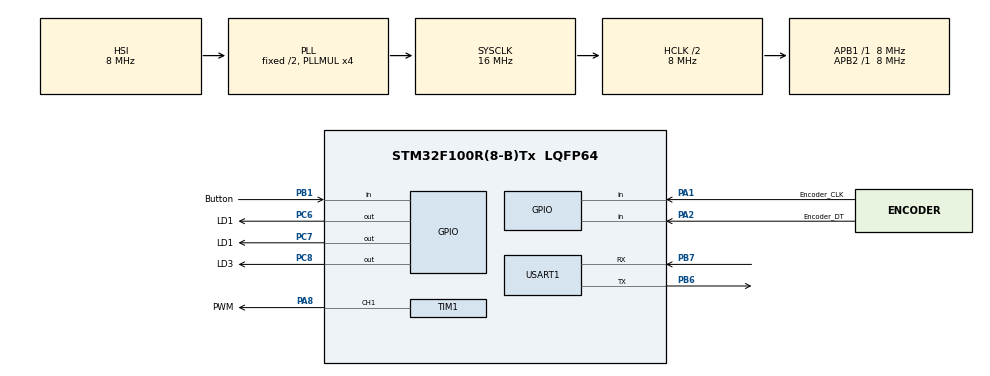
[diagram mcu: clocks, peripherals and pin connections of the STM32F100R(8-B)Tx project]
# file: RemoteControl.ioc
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Mcu.Family=STM32F1
Mcu.Name=STM32F100R(8-B)Tx
Mcu.Package=LQFP64
NVIC.PriorityGroup=NVIC_PRIORITYGROUP_4
NVIC.TIM1_UP_TIM16_IRQn=true\:0\:0\:false\:true\:true\:1\:true
NVIC.TIM6_DAC_IRQn=true\:0\:0\:false\:true\:true\:3\:true
NVIC.USART1_IRQn=true\:0\:0\:false\:true\:true\:2\:true
PA0-WKUP.Signal=SYS_WKUP
PA1.GPIO_Label=Encoder_CLK
PA1.GPIO_PuPd=GPIO_PULLDOWN
PA1.Signal=GPIO_Input
PA13.GPIO_Label=TMS_SWDIO
PA13.Mode=Trace_Asynchronous_SW
PA13.Signal=SYS_JTMS-SWDIO
PA14.GPIO_Label=TCK_SWCLK
PA14.Mode=Trace_Asynchronous_SW
PA14.Signal=SYS_JTCK-SWCLK
PA2.GPIO_Label=Encoder_DT
PA2.GPIO_PuPd=GPIO_PULLDOWN
PA2.Signal=GPIO_Input
PA8.GPIO_Label=PWM
PA8.GPIO_Speed=GPIO_SPEED_FREQ_HIGH
PA8.Signal=S_TIM1_CH1
PB1.GPIO_Label=Button
PB1.GPIO_PuPd=GPIO_PULLDOWN
PB1.Signal=GPIO_Input
PB3.Mode=Trace_Asynchronous_SW
PB3.Signal=SYS_JTDO-TRACESWO
PB6.Mode=Asynchronous
PB6.Signal=USART1_TX
PB7.Mode=Asynchronous
PB7.Signal=USART1_RX
PC14-OSC32_IN.Signal=RCC_OSC32_IN
PC15-OSC32_OUT.Signal=RCC_OSC32_OUT
PC6.GPIO_Label=LD1
PC6.GPIO_Speed=GPIO_SPEED_FREQ_HIGH
PC6.PinState=GPIO_PIN_SET
PC6.Signal=GPIO_Output
PC7.GPIO_Label=LD1
PC7.GPIO_Speed=GPIO_SPEED_FREQ_HIGH
PC7.PinState=GPIO_PIN_SET
PC7.Signal=GPIO_Output
PC8.GPIO_Label=LD3
PC8.GPIO_Speed=GPIO_SPEED_FREQ_HIGH
PC8.PinState=GPIO_PIN_SET
PC8.Signal=GPIO_Output
ProjectManager.HeapSize=0x200
ProjectManager.StackSize=0x400
ProjectManager.TargetToolchain=MDK-ARM V4
RCC.AHBCLKDivider=RCC_SYSCLK_DIV2
RCC.AHBFreq_Value=8000000
RCC.APB1Freq_Value=8000000
RCC.APB1TimFreq_Value=8000000
RCC.APB2Freq_Value=8000000
RCC.APB2TimFreq_Value=8000000
RCC.HCLKFreq_Value=8000000
RCC.PLLMUL=RCC_PLL_MUL4
RCC.SYSCLKFreq_VALUE=16000000
RCC.SYSCLKSource=RCC_SYSCLKSOURCE_PLLCLK
SH.S_TIM1_CH1.0=TIM1_CH1,PWM Generation1 CH1
TIM1.Channel-PWM\ Generation1\ CH1=TIM_CHANNEL_1
TIM1.Period=50000
TIM1.Prescaler=11
USART1.VirtualMode=VM_ASYNC
VP_TIM6_VS_ClockSourceINT.Mode=Enable_Timer
board=STM32VLDISCOVERY

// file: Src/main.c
/**
  ******************************************************************************
  * File Name          : main.c
  * Description        : Main program body
  ******************************************************************************
  ** This notice applies to any and all portions of this file
  * that are not between comment pairs USER CODE BEGIN and
  * USER CODE END. Other portions of this file, whether
  * inserted by the user or by software development tools
  * are owned by their respective copyright owners.
  *
  * COPYRIGHT(c) 2018 STMicroelectronics
  *
  * Redistribution and use in source and binary forms, with or without modification,
  * are permitted provided that the following conditions are met:
  *   1. Redistributions of source code must retain the above copyright notice,
  *      this list of conditions and the following disclaimer.
  *   2. Redistributions in binary form must reproduce the above copyright notice,
  *      this list of conditions and the following disclaimer in the documentation
  *      and/or other materials provided with the distribution.
  *   3. Neither the name of STMicroelectronics nor the names of its contributors
  *      may be used to endorse or promote products derived from this software
  *      without specific prior written permission.
  *
  * THIS SOFTWARE IS PROVIDED BY THE COPYRIGHT HOLDERS AND CONTRIBUTORS "AS IS"
  * AND ANY EXPRESS OR IMPLIED WARRANTIES, INCLUDING, BUT NOT LIMITED TO, THE
  * IMPLIED WARRANTIES OF MERCHANTABILITY AND FITNESS FOR A PARTICULAR PURPOSE ARE
  * DISCLAIMED. IN NO EVENT SHALL THE COPYRIGHT HOLDER OR CONTRIBUTORS BE LIABLE
  * FOR ANY DIRECT, INDIRECT, INCIDENTAL, SPECIAL, EXEMPLARY, OR CONSEQUENTIAL
  * DAMAGES (INCLUDING, BUT NOT LIMITED TO, PROCUREMENT OF SUBSTITUTE GOODS OR
  * SERVICES; LOSS OF USE, DATA, OR PROFITS; OR BUSINESS INTERRUPTION) HOWEVER
  * CAUSED AND ON ANY THEORY OF LIABILITY, WHETHER IN CONTRACT, STRICT LIABILITY,
  * OR TORT (INCLUDING NEGLIGENCE OR OTHERWISE) ARISING IN ANY WAY OUT OF THE USE
  * OF THIS SOFTWARE, EVEN IF ADVISED OF THE POSSIBILITY OF SUCH DAMAGE.
  *
  ******************************************************************************
  */

#include "main.h"
#include "stm32f1xx_hal.h"

/* USER CODE BEGIN Includes */

/* Modbus RTU */
#include "mb.h"
#include "mbport.h"
#include "registers.h"

/* USER CODE END Includes */

TIM_HandleTypeDef htim1;
TIM_HandleTypeDef htim6;

UART_HandleTypeDef huart1;

/* USER CODE BEGIN PV */
/* Private variables ---------------------------------------------------------*/

/* USER CODE END PV */

void SystemClock_Config(void);
static void MX_GPIO_Init(void);
static void MX_TIM1_Init(void);
static void MX_TIM6_Init(void);
static void MX_USART1_UART_Init(void);
static void MX_NVIC_Init(void);
void HAL_TIM_MspPostInit(TIM_HandleTypeDef *htim);

/* USER CODE BEGIN PFP */
/* Private function prototypes -----------------------------------------------*/

/* USER CODE END PFP */

int main(void)
{

  /* MCU Configuration----------------------------------------------------------*/

  /* Reset of all peripherals, Initializes the Flash interface and the Systick. */
  HAL_Init();

  /* Configure the system clock */
  SystemClock_Config();

  /* Initialize all configured peripherals */
  MX_GPIO_Init();
  MX_TIM1_Init();
  MX_TIM6_Init();
  MX_USART1_UART_Init();

  /* Initialize interrupts */
  MX_NVIC_Init();

  /* USER CODE BEGIN 2 */
  HAL_TIM_PWM_Start(&htim1, TIM_CHANNEL_1);
  eMBInit(MB_RTU, SLAVE_ADDRESS, USB, BAUDRATE, MB_PAR_NONE);
  eMBEnable();
  /* USER CODE END 2 */

  /* Infinite loop */
  /* USER CODE BEGIN WHILE */
  while (1)
  {
    static float PWM_duty = 0, TIM_period = 0, PWM_value = 0, analog_value = 0;
    static char button, led1, led2, led3, led_flag, prev_pos, counter_DT, counter_clk;
    static int  counter = 0;
    button = HAL_GPIO_ReadPin(GPIOB, GPIO_PIN_1);
    counter_DT = HAL_GPIO_ReadPin(GPIOA, GPIO_PIN_2);
    counter_clk = HAL_GPIO_ReadPin(GPIOA, GPIO_PIN_1);

    /* HC-SR04 value (echo) to % */
    /*
    if ((counter_echo_flag == ON) && (echo_pulse == ON))
      counter_echo++;
    else if ((counter_echo_flag == ON) && (echo_pulse == OFF))
      counter_echo_flag = OFF;
    if ((button_stm32 == ON) || (trigger_flag == OFF))
    {
        counter_echo_flag == ON;
        trigger_flag = ON;
    }
    if (trigger_flag == ON)
		{
      for (int i = 0; i < 50; i++)
				HAL_GPIO_WritePin(GPIOC, GPIO_PIN_6, GPIO_PIN_SET);
			HAL_GPIO_WritePin(GPIOC, GPIO_PIN_6, GPIO_PIN_RESET);
		}
    */

    /* Encoder code */
    if (counter_DT != prev_pos)
        {
            if (counter_DT != counter_clk)
              analog_value = analog_value + 1;
            else
              analog_value = analog_value - 1;;
            if (analog_value >= 100)
              analog_value = 100;
            if (analog_value <= 0)
              analog_value = 0;
        }

    /* Main logic */
    if (button == OFF)
    {
      if (analog_value < 20)
      {
        led1 = ON;
        led2 = ON;
        led3 = ON;
        PWM_value = 0;
      }
      if ((analog_value >= 20) && (analog_value < 60))
      {
        counter++;
        if (led_flag == OFF)
        {
          if (counter < LED_BLINK)
          {
            led1 = OFF;
            led_flag = OFF;
          }
          else if (counter > LED_BLINK)
          {
            led_flag = ON;
            counter = 0;
          }
        }
        if (led_flag == ON)
        {
          if (counter < LED_BLINK)
          {
            led1 = ON;
            led_flag = ON;
          }
          else if (counter > LED_BLINK)
          {
            led_flag = OFF;
            counter = 0;
          }
        }
        PWM_value = analog_value;
      }
      if ((analog_value >= 60) && (analog_value < 90))
      {
        led1 = ON;
        led3 = ON;
        counter++;
        if (led_flag == OFF)
        {
          if (counter < LED_BLINK)
          {
            led2 = OFF;
            led_flag = OFF;
          }
          else if (counter > LED_BLINK)
          {
            led_flag = ON;
            counter = 0;
          }
        }
        if (led_flag == ON)
        {
          if (counter < LED_BLINK)
          {
            led2 = ON;
            led_flag = ON;
          }
          else if (counter > LED_BLINK)
          {
            led_flag = OFF;
            counter = 0;
          }
        }

        PWM_value = 60;
      }
      if (analog_value >= 90)
      {
        led1 = ON;
        led2 = ON;
        counter++;
        if (led_flag == OFF)
        {
          if (counter < LED_BLINK)
          {
            led3 = OFF;
            led_flag = OFF;
          }
          else if (counter > LED_BLINK)
          {
            led_flag = ON;
            counter = 0;
          }
        }
        if (led_flag == ON)
        {
          if (counter < LED_BLINK)
          {
            led3 = ON;
            led_flag = ON;
          }
          else if (counter > LED_BLINK)
          {
            led_flag = OFF;
            counter = 0;
          }
        }
        PWM_value = 0;
      }
    }
    else if (button == ON)
    {
      led1 = OFF;
      led2 = OFF;
      counter++;
      if (led_flag == OFF)
      {
          if (counter < LED_BLINK)
          {
            led3 = OFF;
            led_flag = OFF;
          }
          else if (counter > LED_BLINK)
          {
            led_flag = ON;
            counter = 0;
          }
      }
      if (led_flag == ON)
      {
        if (counter < LED_BLINK)
        {
          led3 = ON;
          led_flag = ON;
        }
        else if (counter > LED_BLINK)
        {
          led_flag = OFF;
          counter = 0;
        }
      }
    PWM_value = (0.3333 * (analog_value));
		}

    if (led3 == ON)
      HAL_GPIO_WritePin(GPIOC, GPIO_PIN_9, GPIO_PIN_SET);
    else
      HAL_GPIO_WritePin(GPIOC, GPIO_PIN_9, GPIO_PIN_RESET);
    if (led1 == ON)
      HAL_GPIO_WritePin(GPIOC, GPIO_PIN_7, GPIO_PIN_SET);
    else
      HAL_GPIO_WritePin(GPIOC, GPIO_PIN_7, GPIO_PIN_RESET);
    if (led2 == ON)
      HAL_GPIO_WritePin(GPIOC, GPIO_PIN_8, GPIO_PIN_SET);
    else
      HAL_GPIO_WritePin(GPIOC, GPIO_PIN_8, GPIO_PIN_RESET);

    /* PWM duty by PWM_value in precent */
    htim1.Instance = TIM1;
    TIM_period = htim1.Instance->ARR;
    PWM_duty = TIM_period * (PWM_value / 100);
    htim1.Instance->CCR1 = PWM_duty;

    LED_1 = led1;
    LED_2 = led2;
    LED_3 = led3;
    BUTTON_VALUE = button;
    PWM_VALUE = PWM_value;
    ANALOG_VALUE = analog_value;
    prev_pos = HAL_GPIO_ReadPin(GPIOA, GPIO_PIN_2);
    eMBPoll();

  /* USER CODE END WHILE */

  }

}

/** System Clock Configuration
*/
void SystemClock_Config(void)
{

  RCC_OscInitTypeDef RCC_OscInitStruct;
  RCC_ClkInitTypeDef RCC_ClkInitStruct;

    /**Initializes the CPU, AHB and APB busses clocks
    */
  RCC_OscInitStruct.OscillatorType = RCC_OSCILLATORTYPE_HSI;
  RCC_OscInitStruct.HSIState = RCC_HSI_ON;
  RCC_OscInitStruct.HSICalibrationValue = 16;
  RCC_OscInitStruct.PLL.PLLState = RCC_PLL_ON;
  RCC_OscInitStruct.PLL.PLLSource = RCC_PLLSOURCE_HSI_DIV2;
  RCC_OscInitStruct.PLL.PLLMUL = RCC_PLL_MUL4;
  if (HAL_RCC_OscConfig(&RCC_OscInitStruct) != HAL_OK)
  {
    _Error_Handler(__FILE__, __LINE__);
  }

    /**Initializes the CPU, AHB and APB busses clocks
    */
  RCC_ClkInitStruct.ClockType = RCC_CLOCKTYPE_HCLK|RCC_CLOCKTYPE_SYSCLK
                              |RCC_CLOCKTYPE_PCLK1|RCC_CLOCKTYPE_PCLK2;
  RCC_ClkInitStruct.SYSCLKSource = RCC_SYSCLKSOURCE_PLLCLK;
  RCC_ClkInitStruct.AHBCLKDivider = RCC_SYSCLK_DIV2;
  RCC_ClkInitStruct.APB1CLKDivider = RCC_HCLK_DIV1;
  RCC_ClkInitStruct.APB2CLKDivider = RCC_HCLK_DIV1;

  if (HAL_RCC_ClockConfig(&RCC_ClkInitStruct, FLASH_LATENCY_0) != HAL_OK)
  {
    _Error_Handler(__FILE__, __LINE__);
  }

    /**Configure the Systick interrupt time
    */
  HAL_SYSTICK_Config(HAL_RCC_GetHCLKFreq()/1000);

    /**Configure the Systick
    */
  HAL_SYSTICK_CLKSourceConfig(SYSTICK_CLKSOURCE_HCLK);

  /* SysTick_IRQn interrupt configuration */
  HAL_NVIC_SetPriority(SysTick_IRQn, 0, 0);
}

/** NVIC Configuration
*/
static void MX_NVIC_Init(void)
{
  /* TIM1_UP_TIM16_IRQn interrupt configuration */
  HAL_NVIC_SetPriority(TIM1_UP_TIM16_IRQn, 0, 0);
  HAL_NVIC_EnableIRQ(TIM1_UP_TIM16_IRQn);
  /* USART1_IRQn interrupt configuration */
  HAL_NVIC_SetPriority(USART1_IRQn, 0, 0);
  HAL_NVIC_EnableIRQ(USART1_IRQn);
  /* TIM6_DAC_IRQn interrupt configuration */
  HAL_NVIC_SetPriority(TIM6_DAC_IRQn, 0, 0);
  HAL_NVIC_EnableIRQ(TIM6_DAC_IRQn);
}

/* TIM1 init function */
static void MX_TIM1_Init(void)
{

  TIM_MasterConfigTypeDef sMasterConfig;
  TIM_OC_InitTypeDef sConfigOC;
  TIM_BreakDeadTimeConfigTypeDef sBreakDeadTimeConfig;

  htim1.Instance = TIM1;
  htim1.Init.Prescaler = 11;
  htim1.Init.CounterMode = TIM_COUNTERMODE_UP;
  htim1.Init.Period = 50000;
  htim1.Init.ClockDivision = TIM_CLOCKDIVISION_DIV1;
  htim1.Init.RepetitionCounter = 0;
  htim1.Init.AutoReloadPreload = TIM_AUTORELOAD_PRELOAD_DISABLE;
  if (HAL_TIM_PWM_Init(&htim1) != HAL_OK)
  {
    _Error_Handler(__FILE__, __LINE__);
  }

  sMasterConfig.MasterOutputTrigger = TIM_TRGO_RESET;
  sMasterConfig.MasterSlaveMode = TIM_MASTERSLAVEMODE_DISABLE;
  if (HAL_TIMEx_MasterConfigSynchronization(&htim1, &sMasterConfig) != HAL_OK)
  {
    _Error_Handler(__FILE__, __LINE__);
  }

  sConfigOC.OCMode = TIM_OCMODE_PWM1;
  sConfigOC.Pulse = 0;
  sConfigOC.OCPolarity = TIM_OCPOLARITY_HIGH;
  sConfigOC.OCNPolarity = TIM_OCNPOLARITY_HIGH;
  sConfigOC.OCFastMode = TIM_OCFAST_DISABLE;
  sConfigOC.OCIdleState = TIM_OCIDLESTATE_RESET;
  sConfigOC.OCNIdleState = TIM_OCNIDLESTATE_RESET;
  if (HAL_TIM_PWM_ConfigChannel(&htim1, &sConfigOC, TIM_CHANNEL_1) != HAL_OK)
  {
    _Error_Handler(__FILE__, __LINE__);
  }

  sBreakDeadTimeConfig.OffStateRunMode = TIM_OSSR_DISABLE;
  sBreakDeadTimeConfig.OffStateIDLEMode = TIM_OSSI_DISABLE;
  sBreakDeadTimeConfig.LockLevel = TIM_LOCKLEVEL_OFF;
  sBreakDeadTimeConfig.DeadTime = 0;
  sBreakDeadTimeConfig.BreakState = TIM_BREAK_DISABLE;
  sBreakDeadTimeConfig.BreakPolarity = TIM_BREAKPOLARITY_HIGH;
  sBreakDeadTimeConfig.AutomaticOutput = TIM_AUTOMATICOUTPUT_DISABLE;
  if (HAL_TIMEx_ConfigBreakDeadTime(&htim1, &sBreakDeadTimeConfig) != HAL_OK)
  {
    _Error_Handler(__FILE__, __LINE__);
  }

  HAL_TIM_MspPostInit(&htim1);

}

/* TIM6 init function */
static void MX_TIM6_Init(void)
{

  TIM_MasterConfigTypeDef sMasterConfig;

  htim6.Instance = TIM6;
  htim6.Init.Prescaler = 0;
  htim6.Init.CounterMode = TIM_COUNTERMODE_UP;
  htim6.Init.Period = 0;
  htim6.Init.AutoReloadPreload = TIM_AUTORELOAD_PRELOAD_DISABLE;
  if (HAL_TIM_Base_Init(&htim6) != HAL_OK)
  {
    _Error_Handler(__FILE__, __LINE__);
  }

  sMasterConfig.MasterOutputTrigger = TIM_TRGO_RESET;
  sMasterConfig.MasterSlaveMode = TIM_MASTERSLAVEMODE_DISABLE;
  if (HAL_TIMEx_MasterConfigSynchronization(&htim6, &sMasterConfig) != HAL_OK)
  {
    _Error_Handler(__FILE__, __LINE__);
  }

}

/* USART1 init function */
static void MX_USART1_UART_Init(void)
{

  huart1.Instance = USART1;
  huart1.Init.BaudRate = 115200;
  huart1.Init.WordLength = UART_WORDLENGTH_8B;
  huart1.Init.StopBits = UART_STOPBITS_1;
  huart1.Init.Parity = UART_PARITY_NONE;
  huart1.Init.Mode = UART_MODE_TX_RX;
  huart1.Init.HwFlowCtl = UART_HWCONTROL_NONE;
  huart1.Init.OverSampling = UART_OVERSAMPLING_16;
  if (HAL_UART_Init(&huart1) != HAL_OK)
  {
    _Error_Handler(__FILE__, __LINE__);
  }

}

/** Configure pins as
        * Analog
        * Input
        * Output
        * EVENT_OUT
        * EXTI
*/
static void MX_GPIO_Init(void)
{

  GPIO_InitTypeDef GPIO_InitStruct;

  /* GPIO Ports Clock Enable */
  __HAL_RCC_GPIOC_CLK_ENABLE();
  __HAL_RCC_GPIOA_CLK_ENABLE();
  __HAL_RCC_GPIOB_CLK_ENABLE();

  /*Configure GPIO pin Output Level */
  HAL_GPIO_WritePin(GPIOC, LD1_Pin|LD2_Pin|LD3_Pin, GPIO_PIN_SET);

  /*Configure GPIO pins : Encoder_CLK_Pin Encoder_DT_Pin */
  GPIO_InitStruct.Pin = Encoder_CLK_Pin|Encoder_DT_Pin;
  GPIO_InitStruct.Mode = GPIO_MODE_INPUT;
  GPIO_InitStruct.Pull = GPIO_PULLDOWN;
  HAL_GPIO_Init(GPIOA, &GPIO_InitStruct);

  /*Configure GPIO pin : Button_Pin */
  GPIO_InitStruct.Pin = Button_Pin;
  GPIO_InitStruct.Mode = GPIO_MODE_INPUT;
  GPIO_InitStruct.Pull = GPIO_PULLDOWN;
  HAL_GPIO_Init(Button_GPIO_Port, &GPIO_InitStruct);

  /*Configure GPIO pins : LD1_Pin LD1C7_Pin LD3_Pin */
  GPIO_InitStruct.Pin = LD1_Pin|LD2_Pin|LD3_Pin;
  GPIO_InitStruct.Mode = GPIO_MODE_OUTPUT_PP;
  GPIO_InitStruct.Speed = GPIO_SPEED_FREQ_HIGH;
  HAL_GPIO_Init(GPIOC, &GPIO_InitStruct);

}

void _Error_Handler(char * file, int line)
{
  while(1)
  {
  }
}

/************************ (C) COPYRIGHT STMicroelectronics *****END OF FILE****/
